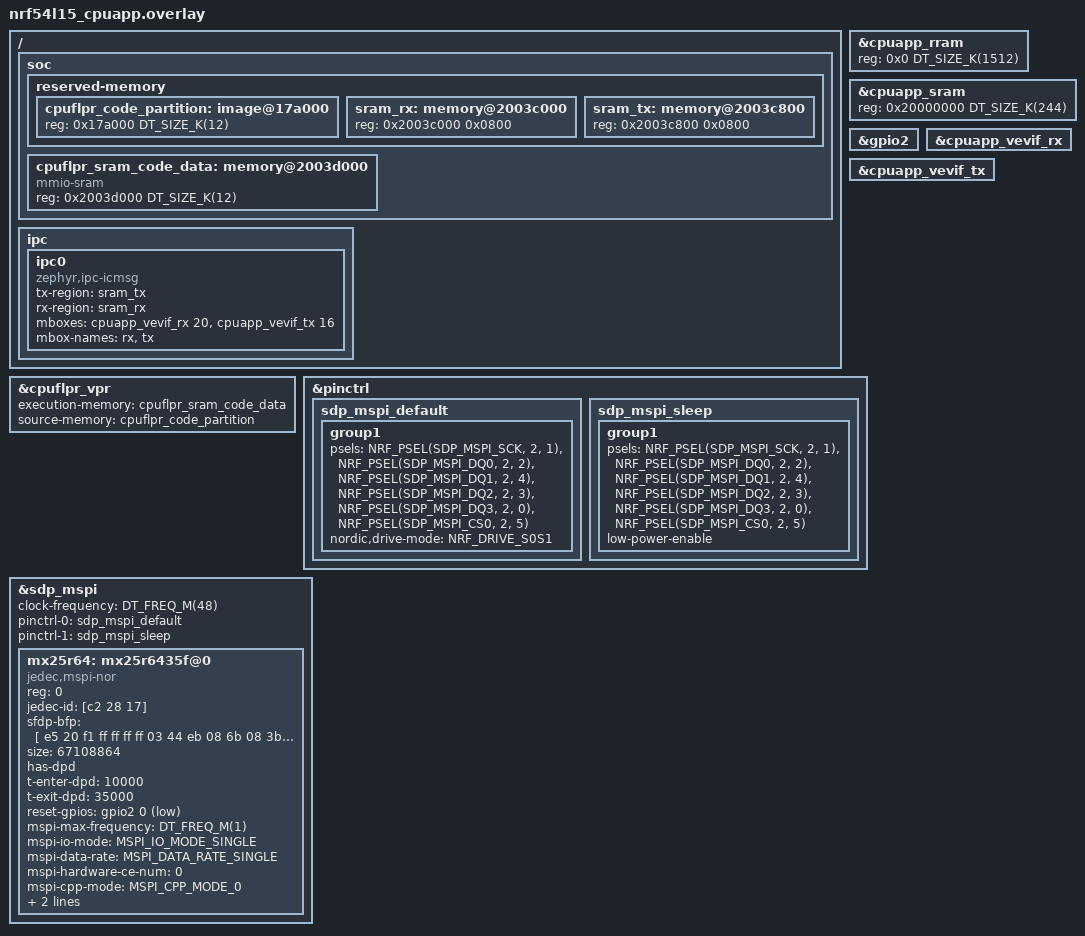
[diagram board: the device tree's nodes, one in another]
/*
 * Copyright (c) 2024 Nordic Semiconductor ASA
 *
 * SPDX-License-Identifier: LicenseRef-Nordic-5-Clause
 */

/ {
	soc {
		reserved-memory {
			#address-cells = <1>;
			#size-cells = <1>;

			cpuflpr_code_partition: image@17a000 {
				reg = <0x17a000 DT_SIZE_K(12)>;
			};

			sram_rx: memory@2003c000 {
				reg = <0x2003c000 0x0800>;
			};

			sram_tx: memory@2003c800 {
				reg = <0x2003c800 0x0800>;
			};
		};


		cpuflpr_sram_code_data: memory@2003d000 {
			compatible = "mmio-sram";
			reg = <0x2003d000 DT_SIZE_K(12)>;
			#address-cells = <1>;
			#size-cells = <1>;
			ranges = <0x0 0x2003d000 0x3000>;
		};
	};

	ipc {
		ipc0: ipc0 {
			compatible = "zephyr,ipc-icmsg";
			tx-region = <&sram_tx>;
			rx-region = <&sram_rx>;
			mboxes = <&cpuapp_vevif_rx 20>, <&cpuapp_vevif_tx 16>;
			mbox-names = "rx", "tx";
			status = "okay";
		};
	};
};

&cpuapp_rram {
	reg = <0x0 DT_SIZE_K(1512)>;
};

&cpuapp_sram {
	reg = <0x20000000 DT_SIZE_K(244)>;
	ranges = <0x0 0x20000000 0x3d000>;
};

&cpuflpr_vpr {
	execution-memory = <&cpuflpr_sram_code_data>;
	source-memory = <&cpuflpr_code_partition>;
};

&gpio2 {
	status = "okay";
};

&cpuapp_vevif_rx {
	status = "okay";
};

&cpuapp_vevif_tx {
	status = "okay";
};

&pinctrl {
	/omit-if-no-ref/ sdp_mspi_default: sdp_mspi_default {
		group1 {
			psels = <NRF_PSEL(SDP_MSPI_SCK, 2, 1)>,
				<NRF_PSEL(SDP_MSPI_DQ0, 2, 2)>,
				<NRF_PSEL(SDP_MSPI_DQ1, 2, 4)>,
				<NRF_PSEL(SDP_MSPI_DQ2, 2, 3)>,
				<NRF_PSEL(SDP_MSPI_DQ3, 2, 0)>,
				<NRF_PSEL(SDP_MSPI_CS0, 2, 5)>;
			nordic,drive-mode = <NRF_DRIVE_S0S1>;
		};
	};
	/omit-if-no-ref/ sdp_mspi_sleep: sdp_mspi_sleep {
		group1 {
			psels = <NRF_PSEL(SDP_MSPI_SCK, 2, 1)>,
				<NRF_PSEL(SDP_MSPI_DQ0, 2, 2)>,
				<NRF_PSEL(SDP_MSPI_DQ1, 2, 4)>,
				<NRF_PSEL(SDP_MSPI_DQ2, 2, 3)>,
				<NRF_PSEL(SDP_MSPI_DQ3, 2, 0)>,
				<NRF_PSEL(SDP_MSPI_CS0, 2, 5)>;
			low-power-enable;
		};
	};
};

/delete-node/ &mx25r64;

&sdp_mspi {
	clock-frequency = <DT_FREQ_M(48)>;
	pinctrl-0 = <&sdp_mspi_default>;
	pinctrl-1 = <&sdp_mspi_sleep>;
	pinctrl-names = "default", "sleep";
	status = "okay";
	mx25r64: mx25r6435f@0 {
		compatible = "jedec,mspi-nor", "zephyr,mspi-emul-device";
		status = "okay";
		reg = <0>;
		jedec-id = [c2 28 17];
		sfdp-bfp = [
			e5 20 f1 ff  ff ff ff 03  44 eb 08 6b  08 3b 04 bb
			ee ff ff ff  ff ff 00 ff  ff ff 00 ff  0c 20 0f 52
			10 d8 00 ff  23 72 f5 00  82 ed 04 cc  44 83 48 44
			30 b0 30 b0  f7 c4 d5 5c  00 be 29 ff  f0 d0 ff ff
		];
		size = <67108864>;
		has-dpd;
		t-enter-dpd = <10000>;
		t-exit-dpd = <35000>;
		reset-gpios = <&gpio2 0 GPIO_ACTIVE_LOW>;

		mspi-max-frequency = <DT_FREQ_M(1)>;
		mspi-io-mode = "MSPI_IO_MODE_SINGLE";
		mspi-data-rate = "MSPI_DATA_RATE_SINGLE";
		mspi-hardware-ce-num = <0>;
		mspi-cpp-mode = "MSPI_CPP_MODE_0";
		mspi-endian = "MSPI_BIG_ENDIAN";
		mspi-ce-polarity = "MSPI_CE_ACTIVE_LOW";
	};
};
